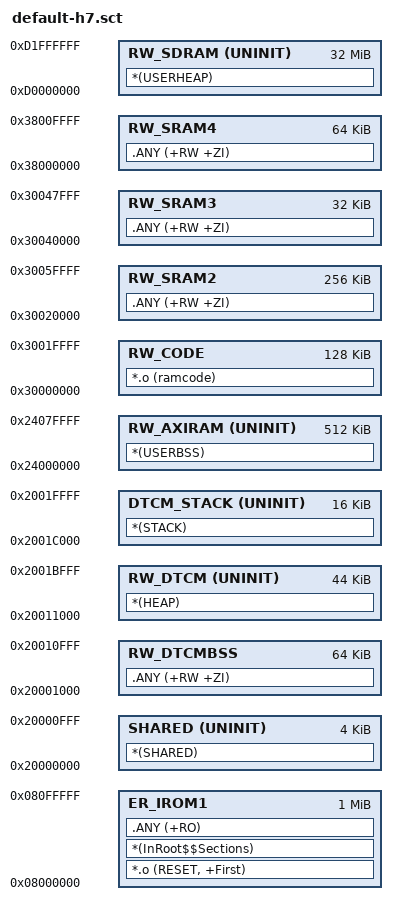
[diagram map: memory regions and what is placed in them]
; *************************************************************
; *** Scatter-Loading Description File generated by uVision ***
; *************************************************************

LR_IROM1 0x08000000 0x00100000  {    ; load region size_region
  ER_IROM1 0x08000000 0x00100000  {  ; load address = execution address
   *.o (RESET, +First)
   *(InRoot$$Sections)
   .ANY (+RO)
  }
  RW_CODE 0x30000000 0x00020000  {  ; SRAM1
   *.o (ramcode)
  }
  SHARED 0x20000000 UNINIT 0x00001000  {  ; DTCM
    *(SHARED)
  }
  RW_DTCMBSS 0x20001000 0x00010000  {  ; DTCM
   .ANY (+RW +ZI)
  }
  RW_DTCM 0x20011000 UNINIT 0x0000B000  {  ; DTCM
   *(HEAP)
  }
; DBG ALGO NOW ON THE BOTTOM OF STACK
  DTCM_STACK 0x2001C000 UNINIT 0x00004000  {  ; DTCM
   *(STACK)
  }
  RW_AXIRAM 0x24000000 UNINIT 0x00080000  {  ; AXI SRAM
   *(USERBSS)
  }
  RW_SDRAM 0xD0000000 UNINIT 0x02000000  {  ; SDRAM
   *(USERHEAP)
  }
  RW_SRAM2 0x30020000 0x00040000  {  ; SRAM2
   .ANY (+RW +ZI)
  }
  RW_SRAM3 0x30040000 0x00008000  {  ; SRAM3
   .ANY (+RW +ZI)
  }
  RW_SRAM4 0x38000000 0x00010000  {  ; SRAM4
   .ANY (+RW +ZI)
  }
}
;0x38801000 - 0x3FFFFFFF Reserved
;0x38800000 - 0x38800FFF Backup SRAM
;0x38010000 - 0x387FFFFF Reserved
;0x38000000 - 0x3800FFFF SRAM4
;0x30048000 - 0x37FFFFFF Reserved
;0x30040000 - 0x30047FFF SRAM3
;0x30020000 - 0x3003FFFF SRAM2
;0x30000000 - 0x3001FFFF SRAM1
;0x24080000 - 0x2FFFFFFF Reserved
;0x24000000 - 0x2407FFFF AXI SRAM
;0x20020000 - 0x23FFFFFF
;0x20000000 - 0x2001FFFF DTCM (Only M7 core)
;0x00000000 - 0x0000FFFF M7 - ITCM; M4 - VTOR REMAP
